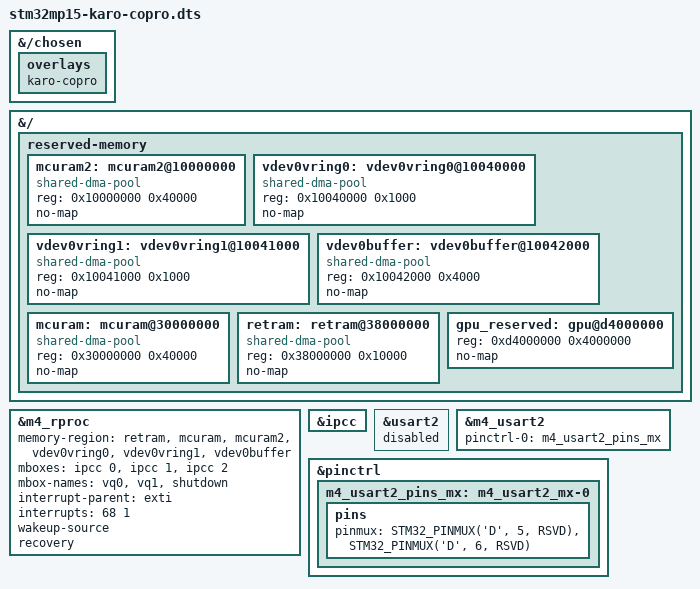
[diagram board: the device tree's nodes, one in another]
// SPDX-License-Identifier: (GPL-2.0 OR BSD-3-Clause)
/*
 * Copyright (C) 2022 Markus Bauer <MB@KARO-electronics.de>
 */

/dts-v1/;

/plugin/;

#include <dt-bindings/pinctrl/stm32-pinfunc.h>

&{/chosen} {
	overlays {
		karo-copro;
	};
};

&{/} {
	reserved-memory {
		#address-cells = <1>;
		#size-cells = <1>;
		ranges;

		mcuram2:mcuram2@10000000{
			compatible = "shared-dma-pool";
			reg = <0x10000000 0x40000>;
			no-map;
		};

		vdev0vring0:vdev0vring0@10040000{
			compatible = "shared-dma-pool";
			reg = <0x10040000 0x1000>;
			no-map;
		};

		vdev0vring1:vdev0vring1@10041000{
			compatible = "shared-dma-pool";
			reg = <0x10041000 0x1000>;
			no-map;
		};

		vdev0buffer:vdev0buffer@10042000{
			compatible = "shared-dma-pool";
			reg = <0x10042000 0x4000>;
			no-map;
		};

		mcuram:mcuram@30000000{
			compatible = "shared-dma-pool";
			reg = <0x30000000 0x40000>;
			no-map;
		};

		retram:retram@38000000{
			compatible = "shared-dma-pool";
			reg = <0x38000000 0x10000>;
			no-map;
		};

		gpu_reserved: gpu@d4000000 {
			reg = <0xd4000000 0x4000000>;
			no-map;
		};
	};
};

&m4_rproc {
	memory-region = <&retram>, <&mcuram>, <&mcuram2>, <&vdev0vring0>,
			<&vdev0vring1>, <&vdev0buffer>;
	mboxes = <&ipcc 0>, <&ipcc 1>, <&ipcc 2>;
	mbox-names = "vq0", "vq1", "shutdown";
	interrupt-parent = <&exti>;
	interrupts = <68 1>;
	interrupt-names = "wdg";
	wakeup-source;
	recovery;
	status = "okay";
};

&ipcc {
	status = "okay";
};

&usart2 {
	status = "disabled";
};

&m4_usart2 {
	pinctrl-names = "default";
	pinctrl-0 = <&m4_usart2_pins_mx>;
	status = "okay";
};

&pinctrl {
	m4_usart2_pins_mx: m4_usart2_mx-0 {
		pins {
			pinmux = <STM32_PINMUX('D', 5, RSVD)>, /* USART2_TX */
				 <STM32_PINMUX('D', 6, RSVD)>; /* USART2_RX */
		};
	};
};
